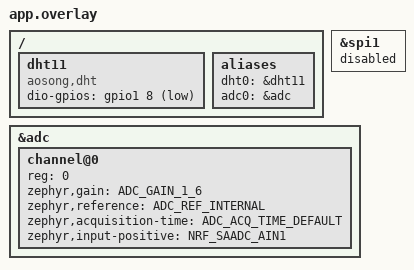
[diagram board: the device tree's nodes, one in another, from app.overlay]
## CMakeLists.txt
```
#
# Copyright (c) 2020 Nordic Semiconductor ASA
#
# SPDX-License-Identifier: LicenseRef-Nordic-5-Clause
#
cmake_minimum_required(VERSION 3.20.0)

find_package(Zephyr REQUIRED HINTS $ENV{ZEPHYR_BASE})
project(Application)

# NORDIC SDK APP START
target_sources(app PRIVATE
	src/main.c
	src/model_handler.c
	src/voltage_sensor.c
    src/dht11.c)
target_include_directories(app PRIVATE include)

# NORDIC SDK APP END
```

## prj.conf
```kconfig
#
# Copyright (c) 2020 Nordic Semiconductor ASA
#
# SPDX-License-Identifier: LicenseRef-Nordic-5-Clause
#
# CONFIG_NCS_SAMPLES_DEFAULTS=y

# Deferred logging helps improve LPN power consumption
# when friendship is established.
CONFIG_LOG_MODE_DEFERRED=y

# General configuration
CONFIG_NCS_APPLICATION_BOOT_BANNER_STRING="Mesh Sensor"
CONFIG_SYSTEM_WORKQUEUE_STACK_SIZE=2048
CONFIG_FLASH=y
CONFIG_FLASH_MAP=y
CONFIG_NVS=y
CONFIG_NVS_LOOKUP_CACHE=y
CONFIG_SETTINGS=y
CONFIG_SETTINGS_NVS_NAME_CACHE=y
CONFIG_HWINFO=y
CONFIG_DK_LIBRARY=y
CONFIG_PM_SINGLE_IMAGE=y
CONFIG_PM_PARTITION_SIZE_SETTINGS_STORAGE=0x8000
CONFIG_SOC_FLASH_NRF_PARTIAL_ERASE=y
CONFIG_FPU=y
CONFIG_CBPRINTF_FP_SUPPORT=y

# Temperature sensor
CONFIG_SENSOR=y
CONFIG_TEMP_NRF5=y

# Bluetooth configuration
CONFIG_BT=y
CONFIG_BT_DEVICE_NAME="Mesh Sensor"
CONFIG_BT_L2CAP_TX_BUF_COUNT=8
CONFIG_BT_OBSERVER=y
CONFIG_BT_PERIPHERAL=y
CONFIG_BT_SETTINGS=y

# Disable unused Bluetooth features
CONFIG_BT_CTLR_LE_ENC=n
CONFIG_BT_PHY_UPDATE=n
CONFIG_BT_CTLR_CHAN_SEL_2=n
CONFIG_BT_CTLR_MIN_USED_CHAN=n
CONFIG_BT_CTLR_PRIVACY=n

# Bluetooth Mesh configuration
CONFIG_BT_MESH=y
CONFIG_BT_MESH_RELAY=y
CONFIG_BT_MESH_FRIEND=y
CONFIG_BT_MESH_TX_SEG_MAX=10
CONFIG_BT_MESH_PB_GATT=y
CONFIG_BT_MESH_GATT_PROXY=y
CONFIG_BT_MESH_PROXY_USE_DEVICE_NAME=y
CONFIG_BT_MESH_DK_PROV=y
CONFIG_BT_MESH_NLC_PERF_CONF=y
CONFIG_BT_MESH_MODEL_EXTENSIONS=y
CONFIG_BT_MESH_MODEL_EXTENSION_LIST_SIZE=10
# Enabling BT_MESH_NLC_PERF_CONF enables support for 3 application keys by
# default. Therefore, allow up to 3 application key bindings per model instance.
CONFIG_BT_MESH_MODEL_KEY_COUNT=3

# Bluetooth Mesh models
CONFIG_BT_MESH_SENSOR_SRV=y
CONFIG_BT_MESH_SENSOR_SRV_SENSORS_MAX=5

# Increase default delayable message config to avoid insuffisient resources
# during normal sample operation
CONFIG_BT_MESH_ACCESS_DELAYABLE_MSG_CHUNK_COUNT=60
CONFIG_BT_MESH_TX_SEG_MSG_COUNT=2
CONFIG_BT_MESH_ACCESS_DELAYABLE_MSG_COUNT=6

# Debugging
CONFIG_BT_MESH_LOG_LEVEL_DBG=y
CONFIG_BT_MESH_PROVISIONEE_LOG_LEVEL_INF=y

# DHT11
CONFIG_STDOUT_CONSOLE=y
CONFIG_SENSOR=y
CONFIG_SENSOR_ASYNC_API=y

# Float Printing
CONFIG_NEWLIB_LIBC=y
CONFIG_NEWLIB_LIBC_FLOAT_PRINTF=y

# ADC
CONFIG_ADC=y
```

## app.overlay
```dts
/ {
    dht11: dht11 {
        compatible = "aosong,dht";
        status = "okay";
        dio-gpios = <&gpio1 8 (GPIO_PULL_UP | GPIO_ACTIVE_LOW)>;
    };

    aliases {
        dht0 = &dht11;
        adc0 = &adc;
    };
};

/* Ensure SPI is explicitly disabled */
&spi1 {
    status = "disabled";
};

&adc {
	#address-cells = <1>;
	#size-cells = <0>;
    status = "okay";

	channel@0 {
        status = "okay";
		reg = <0>;
		zephyr,gain = "ADC_GAIN_1_6";
		zephyr,reference = "ADC_REF_INTERNAL";
		zephyr,acquisition-time = <ADC_ACQ_TIME_DEFAULT>;
		zephyr,input-positive = <NRF_SAADC_AIN1>; /* P0.03 */
	};

};
```

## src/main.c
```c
/*
 * Copyright (c) 2020 Nordic Semiconductor ASA
 *
 * SPDX-License-Identifier: LicenseRef-Nordic-5-Clause
 */

/** @file
 *  @brief Nordic mesh sensor sample
 */
#include <zephyr/bluetooth/bluetooth.h>
#include <bluetooth/mesh/models.h>
#include <bluetooth/mesh/dk_prov.h>
#include <dk_buttons_and_leds.h>
#include <zephyr/drivers/adc.h>
#include <zephyr/logging/log.h>
#include "model_handler.h"

static void bt_ready(int err)
{
	if (err) {
		printk("Bluetooth init failed (err %d)\n", err);
		return;
	}

	printk("Bluetooth initialized\n");

	err = dk_leds_init();
	if (err) {
		printk("Initializing LEDs failed (err %d)\n", err);
		return;
	}

	err = dk_buttons_init(NULL);
	if (err) {
		printk("Initializing buttons failed (err %d)\n", err);
		return;
	}

	err = bt_mesh_init(bt_mesh_dk_prov_init(), model_handler_init());
	if (err) {
		printk("Initializing mesh failed (err %d)\n", err);
		return;
	}

	if (IS_ENABLED(CONFIG_SETTINGS)) {
		settings_load();
	}

	/* This will be a no-op if settings_load() loaded provisioning info */
	bt_mesh_prov_enable(BT_MESH_PROV_ADV | BT_MESH_PROV_GATT);

	printk("Mesh initialized\n");
}

int main(void)
{
	int err;

	printk("Initializing...\n");

	err = bt_enable(bt_ready);
	if (err) {
		printk("Bluetooth init failed (err %d)\n", err);
	}
    
	return 0;
}
```

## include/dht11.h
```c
#pragma once 

int dht_sensor_init(void);
int dht_sensor_read(float *temp, float *hum);
```

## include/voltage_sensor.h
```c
#pragma once


/* Initialize ADC */
int voltage_sensor_init(void);

/* Read ADC channel 0 */
int voltage_sensor_read(float *voltage);
```

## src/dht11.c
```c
/*
 * Copyright (c) 2023 Ian Morris
 *
 * SPDX-License-Identifier: Apache-2.0
 */

#include <stdio.h>
#include <stdlib.h>

#include <zephyr/device.h>
#include <zephyr/sys/util_macro.h>
#include <zephyr/kernel.h>
#include <zephyr/drivers/sensor.h>
#include <zephyr/drivers/sensor_data_types.h>
#include <zephyr/rtio/rtio.h>
#include <zephyr/dsp/print_format.h>

#define DHT_ALIAS DT_ALIAS(dht0)

static const struct device *const sensor = DEVICE_DT_GET(DHT_ALIAS);

SENSOR_DT_READ_IODEV(dht_iodev, DHT_ALIAS,
                     {SENSOR_CHAN_AMBIENT_TEMP, 0},
                     {SENSOR_CHAN_HUMIDITY, 0});

static struct rtio_iodev *dht_iodev_ptr = &dht_iodev;

RTIO_DEFINE(dht_ctx, 1, 1);

float q31_to_float(q31_t q, int shift) {
    char str_value[20]; // Buffer to store the formatted string
    snprintf(str_value, sizeof(str_value), "%s%d.%d", PRIq_arg(q, 2, shift));

    return strtof(str_value, NULL); // Convert string to float
}

/**
 * @brief Initialize the DHT sensor.
 * @return 0 on success, or a negative error code on failure.
 */
int dht_sensor_init(void)
{
    if (!device_is_ready(sensor))
    {
        printk("sensor: device %s not ready.\n", sensor->name);
        return -ENODEV;
    }
    return 0;
}

/**
 * @brief Read temperature and humidity data from the DHT sensor.
 * @param temp Pointer to store the temperature value.
 * @param hum Pointer to store the humidity value.
 * @return 0 on success, or a negative error code on failure.
 */
int dht_sensor_read(float *temp, float *hum)
{
    int rc;
    uint8_t buf[128];

    rc = sensor_read(dht_iodev_ptr, &dht_ctx, buf, 128);
    if (rc != 0)
    {
        printk("%s: sensor_read() failed: %d\n", sensor->name, rc);
        return rc;
    }

    const struct sensor_decoder_api *decoder;
    rc = sensor_get_decoder(sensor, &decoder);
    if (rc != 0)
    {
        printk("%s: sensor_get_decode() failed: %d\n", sensor->name, rc);
        return rc;
    }

    uint32_t temp_fit = 0;
    struct sensor_q31_data temp_data = {0};
    decoder->decode(buf,
                    (struct sensor_chan_spec){SENSOR_CHAN_AMBIENT_TEMP, 0},
                    &temp_fit, 1, &temp_data);

    uint32_t hum_fit = 0;
    struct sensor_q31_data hum_data = {0};
    decoder->decode(buf,
                    (struct sensor_chan_spec){SENSOR_CHAN_HUMIDITY, 0},
                    &hum_fit, 1, &hum_data);

    // printk("temp is %s%d.%d °C humidity is %s%d.%d %%RH\n", PRIq_arg(temp_data.readings[0].temperature, 2, temp_data.shift),
    //     PRIq_arg(hum_data.readings[0].humidity, 2, hum_data.shift));

    // Convert Q31 format to float
    *temp = q31_to_float(temp_data.readings[0].temperature, temp_data.shift);
    *hum = q31_to_float(hum_data.readings[0].humidity, hum_data.shift);

    return 0;
}
```

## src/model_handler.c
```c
/*
 * Copyright (c) 2020 Nordic Semiconductor ASA
 *
 * SPDX-License-Identifier: LicenseRef-Nordic-5-Clause
 */

#include <zephyr/device.h>
#include <zephyr/bluetooth/bluetooth.h>
#include <bluetooth/mesh/models.h>
#include <bluetooth/mesh/sensor_types.h>
#include <zephyr/random/random.h>
#include "model_handler.h"
#include "voltage_sensor.h"
#include "dht11.h"

float temperature, humidity, voltage;
#define TEMP_HUMIDITY_SEND_INTERVAL K_SECONDS(5) // Send data every 10 seconds

static struct k_work_delayable temp_humidity_work;

static int temp_get(struct bt_mesh_sensor_srv *srv,
                    struct bt_mesh_sensor *sensor,
                    struct bt_mesh_msg_ctx *ctx,
                    struct bt_mesh_sensor_value *rsp)
{
    // float dummy_temp = 25.0 + (sys_rand32_get() % 1000) / 100.0; // Random temp between 25.0 - 35.0°C
    int err = bt_mesh_sensor_value_from_float(sensor->type->channels[0].format, temperature, rsp);

    if (err && err != -ERANGE)
    {
        printk("Error encoding temperature (%d)", err);
        return err;
    }

    printk("Getting Temperature: %.2f°C\n", temperature);
    return 0;
}

static int humidity_get(struct bt_mesh_sensor_srv *srv,
                        struct bt_mesh_sensor *sensor,
                        struct bt_mesh_msg_ctx *ctx,
                        struct bt_mesh_sensor_value *rsp)
{
    // float dummy_humid = 50.0 + (sys_rand32_get() % 500) / 10.0; // Random humidity between 50% - 100%
    int err = bt_mesh_sensor_value_from_float(sensor->type->channels[0].format, humidity, rsp);

    if (err && err != -ERANGE)
    {
        printk("Error encoding temperature (%d)", err);
        return err;
    }

    printk("Getting Humidity: %.2f%%\n", humidity);
    return 0;
}

static int voltage_get(struct bt_mesh_sensor_srv *srv,
                       struct bt_mesh_sensor *sensor,
                       struct bt_mesh_msg_ctx *ctx,
                       struct bt_mesh_sensor_value *rsp)
{
    float voltage = 0;
    voltage_sensor_read(&voltage);
    int err = bt_mesh_sensor_value_from_float(sensor->type->channels[0].format, voltage, rsp);

    if (err && err != -ERANGE)
    {
        printk("Error encoding voltage (%d)", err);
        return err;
    }

    printk("Getting Voltage: %.2fV\n", voltage);
    return 0;
}

static struct bt_mesh_sensor temperature_sensor = {
    .type = &bt_mesh_sensor_precise_present_amb_temp,
    .get = temp_get,
};

static struct bt_mesh_sensor humidity_sensor = {
    .type = &bt_mesh_sensor_present_amb_rel_humidity,
    .get = humidity_get,
};

static struct bt_mesh_sensor voltage_sensor = {
    .type = &bt_mesh_sensor_present_input_voltage,
    .get = voltage_get,
};

static struct bt_mesh_sensor *const temperature_sensor_data[] = {
    &temperature_sensor};

static struct bt_mesh_sensor *const humidity_sensor_data[] = {
    &humidity_sensor,
};

static struct bt_mesh_sensor *const voltage_sensor_data[] = {
    &voltage_sensor,
};

static struct bt_mesh_sensor_srv temperature_sensor_srv =
    BT_MESH_SENSOR_SRV_INIT(temperature_sensor_data, ARRAY_SIZE(temperature_sensor_data));
static struct bt_mesh_sensor_srv humidity_sensor_srv =
    BT_MESH_SENSOR_SRV_INIT(humidity_sensor_data, ARRAY_SIZE(humidity_sensor_data));
static struct bt_mesh_sensor_srv voltage_sensor_srv =
    BT_MESH_SENSOR_SRV_INIT(voltage_sensor_data, ARRAY_SIZE(voltage_sensor_data));

static struct bt_mesh_elem elements[] = {
    BT_MESH_ELEM(1,
                 BT_MESH_MODEL_LIST(BT_MESH_MODEL_CFG_SRV,
                                    BT_MESH_MODEL_SENSOR_SRV(&temperature_sensor_srv)),
                 BT_MESH_MODEL_NONE),
    BT_MESH_ELEM(2,
                 BT_MESH_MODEL_LIST(BT_MESH_MODEL_SENSOR_SRV(&humidity_sensor_srv)),
                 BT_MESH_MODEL_NONE),
    BT_MESH_ELEM(3,
                 BT_MESH_MODEL_LIST(BT_MESH_MODEL_SENSOR_SRV(&voltage_sensor_srv)),
                 BT_MESH_MODEL_NONE),
};

static const struct bt_mesh_comp comp = {
    .cid = CONFIG_BT_COMPANY_ID,
    .elem = elements,
    .elem_count = ARRAY_SIZE(elements),
};

static void temp_humidity_send(struct k_work *work)
{
    struct bt_mesh_sensor_value temp_value, humid_value, voltage_value;

    dht_sensor_read(&temperature, &humidity);

    temp_get(NULL, &temperature_sensor, NULL, &temp_value);
    humidity_get(NULL, &humidity_sensor, NULL, &humid_value);
    voltage_get(NULL, &voltage_sensor, NULL, &voltage_value);

    printk("Sending Temperature and Humidity\n");

    bt_mesh_sensor_srv_pub(&temperature_sensor_srv, NULL, &temperature_sensor, &temp_value);
    bt_mesh_sensor_srv_pub(&humidity_sensor_srv, NULL, &humidity_sensor, &humid_value);
    bt_mesh_sensor_srv_pub(&voltage_sensor_srv, NULL, &voltage_sensor, &voltage_value);

    k_work_reschedule(&temp_humidity_work, TEMP_HUMIDITY_SEND_INTERVAL);
}

const struct bt_mesh_comp *model_handler_init(void)
{
    dht_sensor_init();
    voltage_sensor_init();

    k_work_init_delayable(&temp_humidity_work, temp_humidity_send);
    k_work_reschedule(&temp_humidity_work, TEMP_HUMIDITY_SEND_INTERVAL);
    return &comp;
}
```

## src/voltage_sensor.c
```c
#include <zephyr/drivers/adc.h>
#include <zephyr/kernel.h>
#include <zephyr/sys/printk.h>
#include "voltage_sensor.h"

#define ADC_NODE DT_ALIAS(adc0)
#define ADC_RESOLUTION 12
/* Voltage Divider Resistors */
#define R1 100000 /* 100kΩ */
#define R2 6000   /* 6kΩ */

/* Divider Gain Calculation */
#define VOLTAGE_DIVIDER_RATIO ((R1 + R2) / (float)R2)  /* 17.67 */
/* ADC Device */
static const struct device *adc = DEVICE_DT_GET(ADC_NODE);

/* ADC channel configuration for Channel 0 */
static const struct adc_channel_cfg channel_cfg = {
    .gain = ADC_GAIN_1_6,
    .reference = ADC_REF_INTERNAL,
    .acquisition_time = ADC_ACQ_TIME_DEFAULT,
    .channel_id = 0,
    .input_positive = 2, // P0.03
};

/* ADC buffer */
static uint16_t adc_sample;
static uint32_t vref_mv = 0;

/* ADC sequence configuration */
static struct adc_sequence sequence = {
    .channels = BIT(0),
    .buffer = &adc_sample,
    .buffer_size = sizeof(adc_sample),
    .resolution = ADC_RESOLUTION,
};

/* Initialize ADC */
int voltage_sensor_init(void)
{
    if (!device_is_ready(adc)) {
        printk("ADC device not ready\n");
        return -1;
    }

    int err = adc_channel_setup(adc, &channel_cfg);
    if (err) {
        printk("Failed to configure ADC channel (err: %d)\n", err);
        return err;
    }

    if (channel_cfg.reference == ADC_REF_INTERNAL) {
        vref_mv = adc_ref_internal(adc);
    }

    return 0;
}

int voltage_sensor_read(float *voltage)
{
    int err = adc_read(adc, &sequence);
    if (err < 0) {
        printk("ADC read failed (err: %d)\n", err);
        return err;
    }

    int32_t value_mv = adc_sample;
    
    err = adc_raw_to_millivolts(vref_mv, channel_cfg.gain, ADC_RESOLUTION, &value_mv);
    if (err < 0) {
        printf(" (value in mV not available)\n");
        return err;
    }

    *voltage = (value_mv * VOLTAGE_DIVIDER_RATIO) / 1000.f;
    return 0;
}
```
